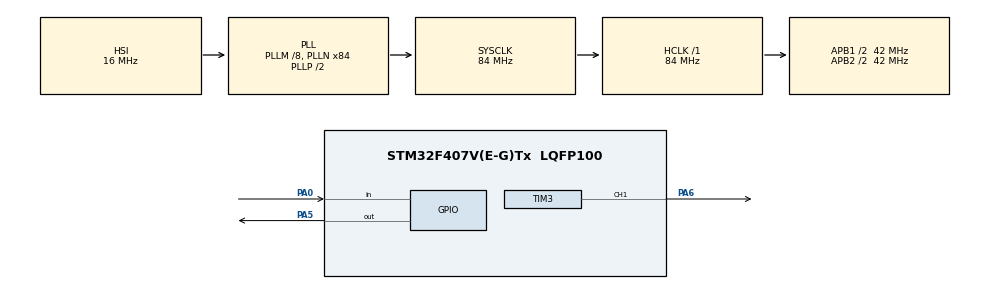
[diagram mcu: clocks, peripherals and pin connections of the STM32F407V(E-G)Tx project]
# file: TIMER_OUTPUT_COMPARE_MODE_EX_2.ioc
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Mcu.Family=STM32F4
Mcu.Name=STM32F407V(E-G)Tx
Mcu.Package=LQFP100
NVIC.PriorityGroup=NVIC_PRIORITYGROUP_0
NVIC.TIM3_IRQn=true\:0\:0\:false\:false\:true\:true\:true\:true
PA0-WKUP.Signal=GPIO_Input
PA5.Signal=GPIO_Output
PA6.Signal=S_TIM3_CH1
PH0-OSC_IN.Mode=HSE-External-Oscillator
PH0-OSC_IN.Signal=RCC_OSC_IN
PH1-OSC_OUT.Mode=HSE-External-Oscillator
PH1-OSC_OUT.Signal=RCC_OSC_OUT
ProjectManager.HeapSize=0x200
ProjectManager.StackSize=0x400
ProjectManager.TargetToolchain=STM32CubeIDE
RCC.48MHZClocksFreq_Value=24000000
RCC.AHBFreq_Value=84000000
RCC.APB1CLKDivider=RCC_HCLK_DIV2
RCC.APB1Freq_Value=42000000
RCC.APB1TimFreq_Value=84000000
RCC.APB2CLKDivider=RCC_HCLK_DIV2
RCC.APB2Freq_Value=42000000
RCC.APB2TimFreq_Value=84000000
RCC.CortexFreq_Value=84000000
RCC.HCLKFreq_Value=84000000
RCC.HSE_VALUE=8000000
RCC.HSI_VALUE=16000000
RCC.PLLM=8
RCC.PLLN=84
RCC.PLLQ=7
RCC.SYSCLKFreq_VALUE=84000000
RCC.SYSCLKSource=RCC_SYSCLKSOURCE_PLLCLK
RCC.VCOOutputFreq_Value=168000000
SH.S_TIM3_CH1.0=TIM3_CH1,Output Compare1 CH1
TIM3.Channel-Output\ Compare1\ CH1=TIM_CHANNEL_1
TIM3.Prescaler=8400
board=STM32F407G-DISC1

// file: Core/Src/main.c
/* USER CODE BEGIN Header */
/**
  ******************************************************************************
  * @file           : main.c
  * @brief          : Main program body
  ******************************************************************************
  * @attention
  *
  * Copyright (c) 2025 STMicroelectronics.
  * All rights reserved.
  *
  * This software is licensed under terms that can be found in the LICENSE file
  * in the root directory of this software component.
  * If no LICENSE file comes with this software, it is provided AS-IS.
  *
  ******************************************************************************
  */
/* USER CODE END Header */
#include "main.h"

TIM_HandleTypeDef htim3;

void SystemClock_Config(void);
static void MX_GPIO_Init(void);
static void MX_TIM3_Init(void);
/* USER CODE BEGIN PFP */
void HAL_TIM_OC_DelayElapsedCallback(TIM_HandleTypeDef *htim);
/* USER CODE END PFP */

int main(void)
{

  /* MCU Configuration--------------------------------------------------------*/

  /* Reset of all peripherals, Initializes the Flash interface and the Systick. */
  HAL_Init();

  /* Configure the system clock */
  SystemClock_Config();

  /* Initialize all configured peripherals */
  MX_GPIO_Init();
  MX_TIM3_Init();
  /* USER CODE BEGIN 2 */
  HAL_TIM_OC_Start_IT(&htim3, TIM_CHANNEL_1);
  /* USER CODE END 2 */

  /* Infinite loop */
  while (1)
  {

    /* USER CODE BEGIN 3 */
	  if(HAL_GPIO_ReadPin(GPIOA, GPIO_PIN_0) == GPIO_PIN_RESET)
	  {
		  uint32_t current = __HAL_TIM_GET_COUNTER(&htim3);

		  __HAL_TIM_SET_COMPARE(&htim3, TIM_CHANNEL_1, current + 20000);
		  HAL_Delay(300);
	  }
  }
  /* USER CODE END 3 */
}

void SystemClock_Config(void)
{
  RCC_OscInitTypeDef RCC_OscInitStruct = {0};
  RCC_ClkInitTypeDef RCC_ClkInitStruct = {0};

  /** Configure the main internal regulator output voltage
  */
  __HAL_RCC_PWR_CLK_ENABLE();
  __HAL_PWR_VOLTAGESCALING_CONFIG(PWR_REGULATOR_VOLTAGE_SCALE1);

  /** Initializes the RCC Oscillators according to the specified parameters
  * in the RCC_OscInitTypeDef structure.
  */
  RCC_OscInitStruct.OscillatorType = RCC_OSCILLATORTYPE_HSI;
  RCC_OscInitStruct.HSIState = RCC_HSI_ON;
  RCC_OscInitStruct.HSICalibrationValue = RCC_HSICALIBRATION_DEFAULT;
  RCC_OscInitStruct.PLL.PLLState = RCC_PLL_ON;
  RCC_OscInitStruct.PLL.PLLSource = RCC_PLLSOURCE_HSI;
  RCC_OscInitStruct.PLL.PLLM = 8;
  RCC_OscInitStruct.PLL.PLLN = 84;
  RCC_OscInitStruct.PLL.PLLP = RCC_PLLP_DIV2;
  RCC_OscInitStruct.PLL.PLLQ = 7;
  if (HAL_RCC_OscConfig(&RCC_OscInitStruct) != HAL_OK)
  {
    Error_Handler();
  }

  /** Initializes the CPU, AHB and APB buses clocks
  */
  RCC_ClkInitStruct.ClockType = RCC_CLOCKTYPE_HCLK|RCC_CLOCKTYPE_SYSCLK
                              |RCC_CLOCKTYPE_PCLK1|RCC_CLOCKTYPE_PCLK2;
  RCC_ClkInitStruct.SYSCLKSource = RCC_SYSCLKSOURCE_PLLCLK;
  RCC_ClkInitStruct.AHBCLKDivider = RCC_SYSCLK_DIV1;
  RCC_ClkInitStruct.APB1CLKDivider = RCC_HCLK_DIV2;
  RCC_ClkInitStruct.APB2CLKDivider = RCC_HCLK_DIV2;

  if (HAL_RCC_ClockConfig(&RCC_ClkInitStruct, FLASH_LATENCY_2) != HAL_OK)
  {
    Error_Handler();
  }
}

static void MX_TIM3_Init(void)
{

  TIM_MasterConfigTypeDef sMasterConfig = {0};
  TIM_OC_InitTypeDef sConfigOC = {0};

  htim3.Instance = TIM3;
  htim3.Init.Prescaler = 8400;
  htim3.Init.CounterMode = TIM_COUNTERMODE_UP;
  htim3.Init.Period = 65535;
  htim3.Init.ClockDivision = TIM_CLOCKDIVISION_DIV1;
  htim3.Init.AutoReloadPreload = TIM_AUTORELOAD_PRELOAD_DISABLE;
  if (HAL_TIM_OC_Init(&htim3) != HAL_OK)
  {
    Error_Handler();
  }
  sMasterConfig.MasterOutputTrigger = TIM_TRGO_RESET;
  sMasterConfig.MasterSlaveMode = TIM_MASTERSLAVEMODE_DISABLE;
  if (HAL_TIMEx_MasterConfigSynchronization(&htim3, &sMasterConfig) != HAL_OK)
  {
    Error_Handler();
  }
  sConfigOC.OCMode = TIM_OCMODE_TIMING;
  sConfigOC.Pulse = 0;
  sConfigOC.OCPolarity = TIM_OCPOLARITY_HIGH;
  sConfigOC.OCFastMode = TIM_OCFAST_DISABLE;
  if (HAL_TIM_OC_ConfigChannel(&htim3, &sConfigOC, TIM_CHANNEL_1) != HAL_OK)
  {
    Error_Handler();
  }
  HAL_TIM_MspPostInit(&htim3);

}

static void MX_GPIO_Init(void)
{
  GPIO_InitTypeDef GPIO_InitStruct = {0};

  /* GPIO Ports Clock Enable */
  __HAL_RCC_GPIOH_CLK_ENABLE();
  __HAL_RCC_GPIOA_CLK_ENABLE();

  /*Configure GPIO pin Output Level */
  HAL_GPIO_WritePin(GPIOA, GPIO_PIN_5, GPIO_PIN_RESET);

  /*Configure GPIO pin : PA0 */
  GPIO_InitStruct.Pin = GPIO_PIN_0;
  GPIO_InitStruct.Mode = GPIO_MODE_INPUT;
  GPIO_InitStruct.Pull = GPIO_NOPULL;
  HAL_GPIO_Init(GPIOA, &GPIO_InitStruct);

  /*Configure GPIO pin : PA5 */
  GPIO_InitStruct.Pin = GPIO_PIN_5;
  GPIO_InitStruct.Mode = GPIO_MODE_OUTPUT_PP;
  GPIO_InitStruct.Pull = GPIO_NOPULL;
  GPIO_InitStruct.Speed = GPIO_SPEED_FREQ_LOW;
  HAL_GPIO_Init(GPIOA, &GPIO_InitStruct);

}

/* USER CODE BEGIN 4 */
void HAL_TIM_OC_DelayElapsedCallback(TIM_HandleTypeDef *htim)
{
	if(htim->Instance == TIM3 && htim->Channel == HAL_TIM_ACTIVE_CHANNEL_1)
	{
		HAL_GPIO_WritePin(GPIOA, GPIO_PIN_5, GPIO_PIN_SET);
	}
}
/* USER CODE END 4 */

void Error_Handler(void)
{
  __disable_irq();
  while (1)
  {
  }
}
